# cm7 register map
Registers are 32-bit, read-write, reset 0x0 unless marked. A register's access mark holds for its fields unless they carry their own. Offsets are from the block's base; [hi:lo] are bit positions; {n}, {i} and the like mark numbered series; 'fields as' and 'values as' point back to an identical list.

## MPU — Memory Protection Unit
Base 0xE000ED90; register names take the prefix MPU_
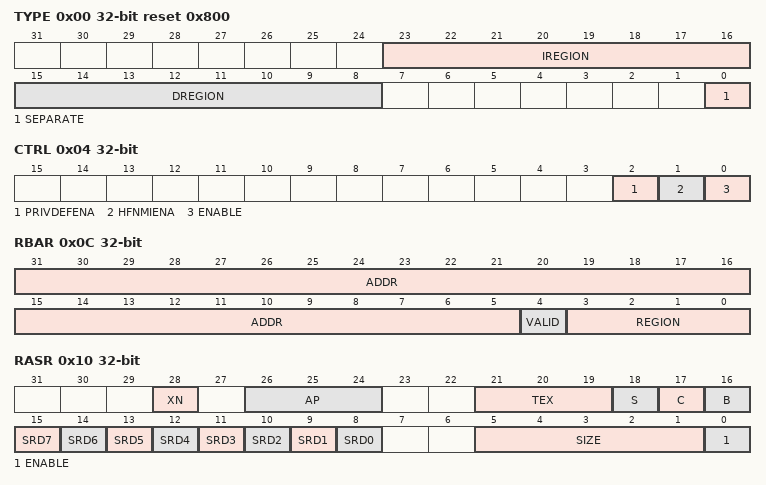
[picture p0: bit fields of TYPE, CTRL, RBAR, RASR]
0x00 TYPE ro reset 0x800 — MPU Type Register
  [23:16] IREGION — Indicates the number of supported MPU instruction regions. Always contains 0x0: the MPU memory map is unified and is described by the DREGION field.
  [15:8] DREGION — Indicates the number of supported MPU data regions depending on your implementation.
  [0] SEPARATE — Indicates support for unified or separate instruction and data memory maps.
    0=Unified (Only unified memory maps are supported.)
0x04 CTRL — MPU Control Register
  [2] PRIVDEFENA — Enables privileged software access to the default memory map.
  [1] HFNMIENA — Enables the operation of MPU during hard fault, NMI, and FAULTMASK handlers.
  [0] ENABLE — Enables the optional MPU.
0x08 RNR — MPU Region Number Register
  [7:0] REGION — Indicates the MPU region referenced by the MPU_RBAR and MPU_RASR registers.
0x0C RBAR — MPU Region Base Address Register
  [31:5] ADDR — The ADDR field is bits[31:N] of the MPU_RBAR. The region size, as specified by the SIZE field in the MPU_RASR, defines the value of N: N = Log2(Region size in bytes). If the region size is configured to 4GB, in the MPU_RASR, there is no valid ADDR field. In this case, the region occupies the complete memory map, and the base address is 0x00000000. The base address is aligned to the size of the region. For example, a 64KB region must be aligned on a multiple of 64KB, for example, at 0x00010000 or 0x00020000.
  [4] VALID — MPU Region number valid bit. Depending on your implementation, this has the following effect: 0 - either updates the base address for the region specified by MPU_RNR or ignores the value of the REGION field. 1 - either updates the value of the MPU_RNR to the value of the REGION field or updates the base address for the region specified in the REGION field.
  [3:0] REGION — On Write, see the VALID field. On read, specifies the region number.
0x10 RASR — MPU Region Base Attribute and Size Register
  [28] XN — Instruction access disable bit
    0=I_Enabled (Instruction fetches enabled.); 1=I_Disabled (Instruction fetches disabled.)
  [26:24] AP — Access permission field
    0=No_Access (All accesses generate a permission fault.); 1=Privileged_RW (Access from privileged software only.); 2=Unpriviledged_RO (Writes by unprivileged software generates a permission fault.); 3=Full_Access; 5=Privileged_RO (Reads by privileged software only.); 6=Read_Only by privileged or unprivileged software; 7=Read_Only by privileged or unprivileged software
  [21:19] TEX — Memory access attribute.
  [18] S — Shareable bit. Applies to Normal memory only.
  [17] C — Memory access attribute.
  [16] B — Memory access attribute.
  [15] SRD7 — Subregion disable bits.
  [14] SRD6 — Subregion disable bits.
  [13] SRD5 — Subregion disable bits.
  [n+8] SRD{n} (n=0..4) — Subregion disable bits
  [5:1] SIZE — Specifies the size of the MPU protection region. Minimum value is 4. The Region size is defined as (Region size in bytes) = 2^(SIZE+1)
  [0] ENABLE — Region enable bit.
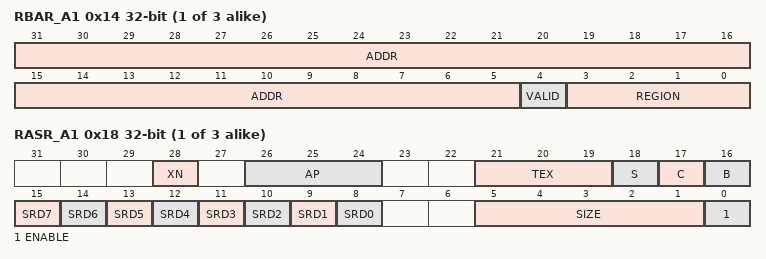
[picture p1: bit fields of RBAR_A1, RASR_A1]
{0xC+8i} RBAR_A{i} (i=1..3) — Uses (MPU_RNR[7:2]<<2) + {i}
  fields as RBAR
{0x10+8i} RASR_A{i} (i=1..3) — Uses (MPU_RNR[7:2]<<2) + {i}
  fields as RASR

## PF — Processor Features
Base 0xE000ED78
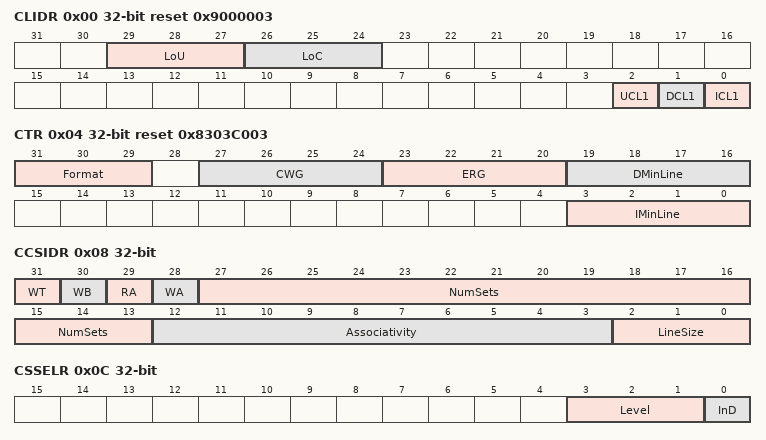
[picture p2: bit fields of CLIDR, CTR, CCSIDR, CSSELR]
0x00 CLIDR ro reset 0x9000003 — Cache Level ID Register
  [29:27] LoU — Level of Unification
    0=Level 1, if neither instruction nor data cache is implemented; 1=Level 2, if either cache is implemented
  [26:24] LoC — Level of Coherency
    values as LoU
  [2] UCL1 — Unified Cache is implemented at L1
  [1] DCL1 — Data Cache is implemented at L1
  [0] ICL1 — An instrumentation Cache is implemented at L1
0x04 CTR ro reset 0x8303C003 — Cache Type Register
  [31:29] Format — Cache Writable Granule.
    4=ARMv7 register forat
  [27:24] CWG — Cache Writable Granule.
    3=Granularity_8_Words (8 words granularity for the Cortex-M7 processor.)
  [23:20] ERG — Exclusive Reservation Granule. The local monitor within the processor does not hold any physical address. It treats any STREX instruction access as matching the address of the previous LDREX instruction. This means that the implemented exclusive reservation granule is the entire memory address range.
  [19:16] DMinLine — Smallest cache line of all the data caches.
    3=Line_8_Words (8 words for the Cortex-M7 processor.)
  [3:0] IMinLine — Smallest cache line of all the instruction caches.
    3=Line_8_Words (8 words for the Cortex-M7 processor.)
0x08 CCSIDR ro — Cache Size ID Register
  [31] WT — Indicates support available for write through.
  [30] WB — Indicates support available for write back.
  [29] RA — Indicates support available for read allocation.
  [28] WA — Indicates support available for write allocation.
  [27:13] NumSets — Indicates the number of sets as (sets - 1)
  [12:3] Associativity — Indicates the number of ways as (ways - 1)
  [2:0] LineSize — Indicates the number of words in each cache line. Encoded as 2 - log(2) number of words. e.g. 0 means 4 words, 1 means 8 words.
0x0C CSSELR — Cache Size Selection Register
  [3:1] Level — Identifies the cache level selected.
    0=Level 1 cache is selected
  [0] InD — Selects the cache currently visible in the CCSIDR.
    0=Data cache is selected; 1=Instruction cache is selected
